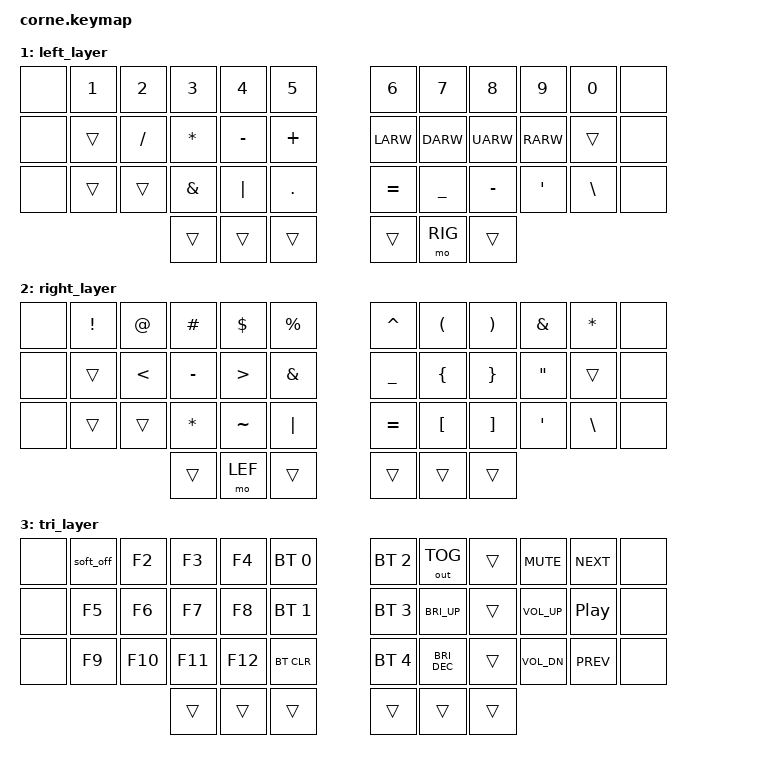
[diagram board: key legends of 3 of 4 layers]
/*
 * Copyright (c) 2024 takiguri
 * Copyright (c) 2020 The ZMK Contributors
 *
 * SPDX-License-Identifier: MIT
 */

#include <behaviors.dtsi>
#include <dt-bindings/zmk/keys.h>
#include <dt-bindings/zmk/bt.h>
#include <dt-bindings/zmk/outputs.h>

// Home row mods macro
#define HRML(k1) &ht LSHIFT k1
#define HRMR(k1) &ht RSHIFT k1

// Bottom row mods macro
#define BRML(k1,k2) &ht LCTRL k1  &ht LALT k2
#define BRMR(k1,k2) &ht RALT k1  &ht RCTRL k2

// Thumb cluster mods macro
#define TRML(k1) &ht LCMD k1
#define TRMR(k1) &ht RCMD k1

#define QWT 0
#define LEF 1
#define RIG 2
#define TRI 3

/ {
    behaviors {
        ht: hold_tap {
            label = "hold_tap";
            compatible = "zmk,behavior-hold-tap";
            #binding-cells = <2>;
            flavor = "tap-preferred";
            tapping-term-ms = <180>;
            quick-tap-ms = <0>;
            global-quick-tap;
            bindings = <&kp>, <&kp>;
        };
    };

    conditional_layers {
        compatible = "zmk,conditional-layers";
        tri_layer {
            if-layers = <RIG LEF>;
            then-layer = <TRI>;
        };
    };

    keymap {
        compatible = "zmk,keymap";
        default_layer {
            bindings = <
        //╭──────────┬──────────┬──────────┬──────────┬──────────╮   ╭──────────┬──────────┬──────────┬──────────┬──────────╮
        //│  Q       │  W       │  E       │  R       │  T       │   │  Y       │  U       │  I       │  O       │  P       │
    &none   &kp Q      &kp W      &kp E      &kp R      &kp T          &kp Y      &kp U      &kp I      &kp O      &kp P      &none
        //├──────────┼──────────┼──────────┼──────────┼──────────┤   ├──────────┼──────────┼──────────┼──────────┼──────────┤
        //│  A       │  S       │  D       │  F       │  G       │   │  H       │  J       │  K       │  L       │ ;        │
    &none   HRML(A)    &kp S      &kp D      &kp F      &kp G          &kp H      &kp J      &kp K      &kp L     HRMR(SEMI)  &none
        //├──────────┼──────────┼──────────┼──────────┼──────────┤   ├──────────┼──────────┼──────────┼──────────┼──────────┤
        //│  Z       │  X       │  C       │  V       │  B       │   │  N       │  M       │ , <      │ . >      │ /        │
    &none   BRML(Z,     X)        &kp C      &kp V      &kp B          &kp N      &kp M      &kp COMMA  BRMR(DOT,  FSLH)      &none
        //╰──────────┴──────────┴──────────┼──────────┼──────────┤   ├──────────┼──────────┼──────────┴──────────┴──────────╯
                                  &kp TAB  &lt LEF ESC TRML(SPACE)    TRMR(RET) &lt RIG BSPC &kp GRAVE
        //                      ╰──────────┴──────────┴──────────╯   ╰──────────┴──────────┴──────────╯
            >;
        };

        left_layer {
                bindings = <
        //╭──────────┬──────────┬──────────┬──────────┬──────────╮   ╭──────────┬──────────┬──────────┬──────────┬──────────╮
        //│ 1        │  2       │  3       │  4       │  5       │   │ 6        │ 7        │ 8        │ 9        │   0      │
    &none   &kp N1    &kp N2     &kp N3     &kp N4     &kp N5          &kp N6     &kp N7     &kp N8     &kp N9      &kp N0    &none
        //├──────────┼──────────┼──────────┼──────────┼──────────┤   ├──────────┼──────────┼──────────┼──────────┼──────────┤
        //│          │  /       │  *       │  -       │  +       |   | LEFT     │ DOWN     │ UP       │ RIGHT    │          │
    &none   &trans     &kp FSLH   &kp STAR   &kp MINUS  &kp PLUS       &kp LARW   &kp DARW   &kp UARW   &kp RARW   &trans     &none
        //├──────────┼──────────┼──────────┼──────────┼──────────┤   ├──────────┼──────────┼──────────┼──────────┼──────────┤
        //│          │          │  &       │  |       │  .       │   │  =       │  _       │  -       │  '       │  \       │
    &none   &trans     &trans     &kp AMPS   &kp PIPE   &kp DOT        &kp EQUAL  &kp UNDER  &kp MINUS  &kp SQT    &kp BSLH   &none 
        //╰──────────┴──────────┴──────────┼──────────┼──────────┤   ├──────────┼──────────┼──────────┴──────────┴──────────╯
                                  &trans     &trans     &trans         &trans     &mo RIG     &trans
        //                      ╰──────────┴──────────┴──────────╯   ╰──────────┴──────────┴──────────╯
            >;
        };

        right_layer {
            bindings = <
        //╭──────────┬──────────┬──────────┬──────────┬──────────╮   ╭──────────┬──────────┬──────────┬──────────┬──────────╮
        //│  !       │  @       │  #       │  $       │  %       │   │  ^       │  (       │  )       │  &       │  *       │
    &none   &kp EXCL   &kp AT     &kp HASH   &kp DLLR   &kp PRCNT      &kp CARET  &kp LPAR   &kp RPAR   &kp AMPS   &kp STAR   &none
        //├──────────┼──────────┼──────────┼──────────┼──────────┤   ├──────────┼──────────┼──────────┼──────────┼──────────┤
        //│          │  <       │  -       │  >       │  &       │   │  _       │  {       │  }       │  ""      │          │
    &none   &trans     &kp LT     &kp MINUS  &kp GT     &kp AMPS       &kp UNDER  &kp LBRC   &kp RBRC   &kp DQT    &trans     &none
        //├──────────┼──────────┼──────────┼──────────┼──────────┤   ├──────────┼──────────┼──────────┼──────────┼──────────┤
        //│          │          │  *       │  ~       │  |       │   │  =       │  [       │  ]       │  '       │  \       │
    &none   &trans     &trans     &kp STAR   &kp TILDE  &kp PIPE      &kp EQUAL   &kp LBKT   &kp RBKT   &kp SQT    &kp BSLH   &none
        //╰──────────┴──────────┴──────────┼──────────┼──────────┤   ├──────────┼──────────┼──────────┴──────────┴──────────╯
                                  &trans     &mo LEF    &trans         &trans     &trans     &trans
        //                      ╰──────────┴──────────┴──────────╯   ╰──────────┴──────────┴──────────╯
            >;
        };

        tri_layer {
            bindings = <
        //╭──────────┬──────────┬──────────┬───────────┬────────────╮   ╭────────────┬────────────┬──────────┬───────────┬──────────╮
        //│  OFF     │  F2      │  F3      │  F4       │ PROFILE 0  │   │ PROFILE 2  │ TOGGLEOUT  │          │ VOL MUTE  │ NEXTSONG │
    &none   &soft_off  &kp F2     &kp F3     &kp F4     &bt BT_SEL 0     &bt BT_SEL 2  &out OUT_TOG  &trans   &kp C_MUTE  &kp C_NEXT  &none
        //├──────────┼──────────┼──────────┼───────────┼────────────┤   ├────────────┼────────────┼──────────┼───────────┼──────────┤
        //│  F5      │  F6      │  F7      │  F8       │ PROFILE 1  │   │ PROFILE 3  │ INC BRIGHT │          │  VOL UP   │PAUSEMUSIC│
    &none   &kp F5     &kp F6     &kp F7     &kp F8     &bt BT_SEL 1     &bt BT_SEL 3  &kp C_BRI_UP  &trans   &kp C_VOL_UP  &kp C_PP  &none
        //├──────────┼──────────┼──────────┼───────────┼────────────┤   ├────────────┼────────────┼──────────┼───────────┼──────────┤
        //│  F9      │  F10     │  F11     │  F12      │  CLEAR BT  │   │ PROFILE 4  │ DEC BRIGHT │          |  VOL DOWN │ PREVSONG │
    &none   &kp F9     &kp F10    &kp F11    &kp F12     &bt BT_CLR      &bt BT_SEL 4  &kp C_BRI_DEC  &trans   &kp C_VOL_DN &kp C_PREV &none
        //╰──────────┴──────────┴──────────┼───────────┼────────────┤   ├────────────┼────────────┼──────────┴───────────┴──────────╯
                                  &trans     &trans      &trans           &trans       &trans       &trans
        //                      ╰──────────┴───────────┴────────────╯   ╰────────────┴────────────┴──────────╯
            >;
        };
    };
};
